VERSION ""

NS_ :

BS_:

BU_:
VAL_TABLE_ VSM_ChrgRequest 1 "Request_acrive" 0 "Not_requested" ;
VAL_TABLE_ VSM_ChrgPlugConnected 1 "Plug_active" 0 "Not_plug" ;
VAL_TABLE_ VSM_ChrgReadyToDrive 1 "Ready_to_drive" 0 "Not_ready" ;

BO_ 3221225472 VECTOR__INDEPENDENT_SIG_MSG: 0 Vector__XXX
 SG_ VSM_ChrgReadyToDrive : 0|1@1+ (1,0) [0|1] "-" Vector__XXX
 SG_ VSM_ChrgPlugConnected : 0|1@1+ (1,0) [0|1] "-" Vector__XXX
 SG_ VSM_ChrgRequest : 0|1@1+ (1,0) [0|1] "-" Vector__XXX
 SG_ VSM_DebugIn6 : 0|1@1+ (1,0) [0|0] "" Vector__XXX
 SG_ VSM_DebugIn5 : 0|1@1+ (1,0) [0|0] "" Vector__XXX
 SG_ VSM_DebugIn4 : 0|1@1+ (1,0) [0|0] "" Vector__XXX
 SG_ VSM_DebugIn3 : 0|1@1+ (1,0) [0|0] "" Vector__XXX
 SG_ VSM_DebugIn2 : 0|1@1+ (1,0) [0|0] "" Vector__XXX
 SG_ VSM_DebugIn1 : 0|1@1+ (1,0) [0|0] "" Vector__XXX

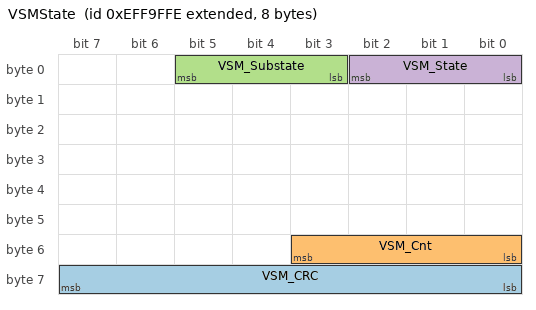
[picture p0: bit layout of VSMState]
BO_ 2399117310 VSMState: 8 Vector__XXX
 SG_ VSM_CRC : 56|8@1+ (1,0) [0|255] "" Vector__XXX
 SG_ VSM_Cnt : 48|4@1+ (1,0) [0|15] "" Vector__XXX
 SG_ VSM_Substate : 3|3@1+ (1,0) [0|7] "" Vector__XXX
 SG_ VSM_State : 0|3@1+ (1,0) [0|7] "" Vector__XXX

CM_ BO_ 3221225472 "This is a message for not used signals, created by Vector CANdb++ DBC OLE DB Provider.";
CM_ BO_ 2399117310 "For DEBUG-TEST only! Consist of signals that can replace AIN siganls from Analog button block";
CM_ SG_ 2399117310 VSM_CRC "Gear selector request from AI";
CM_ SG_ 2399117310 VSM_Cnt "Gear selector request from AI";
CM_ SG_ 2399117310 VSM_State "Gear selector request from AI";
BA_DEF_ BO_  "Producer" STRING ;
BA_DEF_ SG_  "SigType" ENUM  "Default","Range","RangeSigned","ASCII","Discrete","Control","ReferencePGN","DTC","StringDelimiter","StringLength","StringLengthControl","MessageCounter","MessageChecksum";
BA_DEF_ SG_  "GenSigEVName" STRING ;
BA_DEF_ SG_  "GenSigILSupport" ENUM  "No","Yes";
BA_DEF_ SG_  "GenSigSendType" ENUM  "Cyclic","OnWrite","OnWriteWithRepetition","OnChange","OnChangeWithRepetition","IfActive","IfActiveWithRepetition","NoSigSendType";
BA_DEF_ SG_  "GenSigStartValue" INT 0 2147483647;
BA_DEF_ BO_  "GenMsgILSupport" ENUM  "No","Yes";
BA_DEF_ BU_  "NmStationAddress" INT 0 255;
BA_DEF_ BO_  "GenMsgSendType" ENUM  "cyclic","NotUsed","IfActive","NotUsed","NotUsed","NotUsed","NotUsed","NotUsed","noMsgSendType";
BA_DEF_ BO_  "GenMsgRequestable" INT 0 1;
BA_DEF_ BO_  "GenMsgCycleTime" INT 0 3600000;
BA_DEF_  "DBName" STRING ;
BA_DEF_  "BusType" STRING ;
BA_DEF_  "ProtocolType" STRING ;
BA_DEF_ BO_  "VFrameFormat" ENUM  "StandardCAN","ExtendedCAN","reserved","J1939PG";
BA_DEF_DEF_ "Producer" "VSS" ;
BA_DEF_DEF_  "SigType" "Default";
BA_DEF_DEF_  "GenSigEVName" "Env@Nodename_@Signame";
BA_DEF_DEF_  "GenSigILSupport" "Yes";
BA_DEF_DEF_  "GenSigSendType" "NoSigSendType";
BA_DEF_DEF_  "GenSigStartValue" 0;
BA_DEF_DEF_  "GenMsgILSupport" "Yes";
BA_DEF_DEF_  "NmStationAddress" 254;
BA_DEF_DEF_  "GenMsgSendType" "noMsgSendType";
BA_DEF_DEF_  "GenMsgRequestable" 1;
BA_DEF_DEF_  "GenMsgCycleTime" 0;
BA_DEF_DEF_  "DBName" "";
BA_DEF_DEF_  "BusType" "CAN";
BA_DEF_DEF_  "ProtocolType" "J1939";
BA_DEF_DEF_  "VFrameFormat" "J1939PG";
BA_ "DBName" "VSM";
BA_ "GenMsgSendType" BO_ 2399117310 0;
BA_ "GenMsgCycleTime" BO_ 2399117310 100;
BA_ "SigType" SG_ 2399117310 VSM_CRC 12;
BA_ "SigType" SG_ 2399117310 VSM_Cnt 11;
BA_ "GenSigStartValue" SG_ 2399117310 VSM_State 7;
VAL_ 3221225472 VSM_ChrgReadyToDrive 1 "Ready_to_drive" 0 "Not_ready" ;
VAL_ 3221225472 VSM_ChrgPlugConnected 1 "Plug_active" 0 "Not_plug" ;
VAL_ 3221225472 VSM_ChrgRequest 1 "Request_acrive" 0 "Not_requested" ;
VAL_ 2399117310 VSM_Substate 4 "Substate4" 3 "Substate3" 2 "Substate2" 1 "Substate1" 0 "Default" ;
VAL_ 2399117310 VSM_State 7 "NA" 5 "LongTerm Park" 4 "Maintenance" 3 "Charging" 2 "Ready" 1 "Awake" 0 "Sleep" ;
